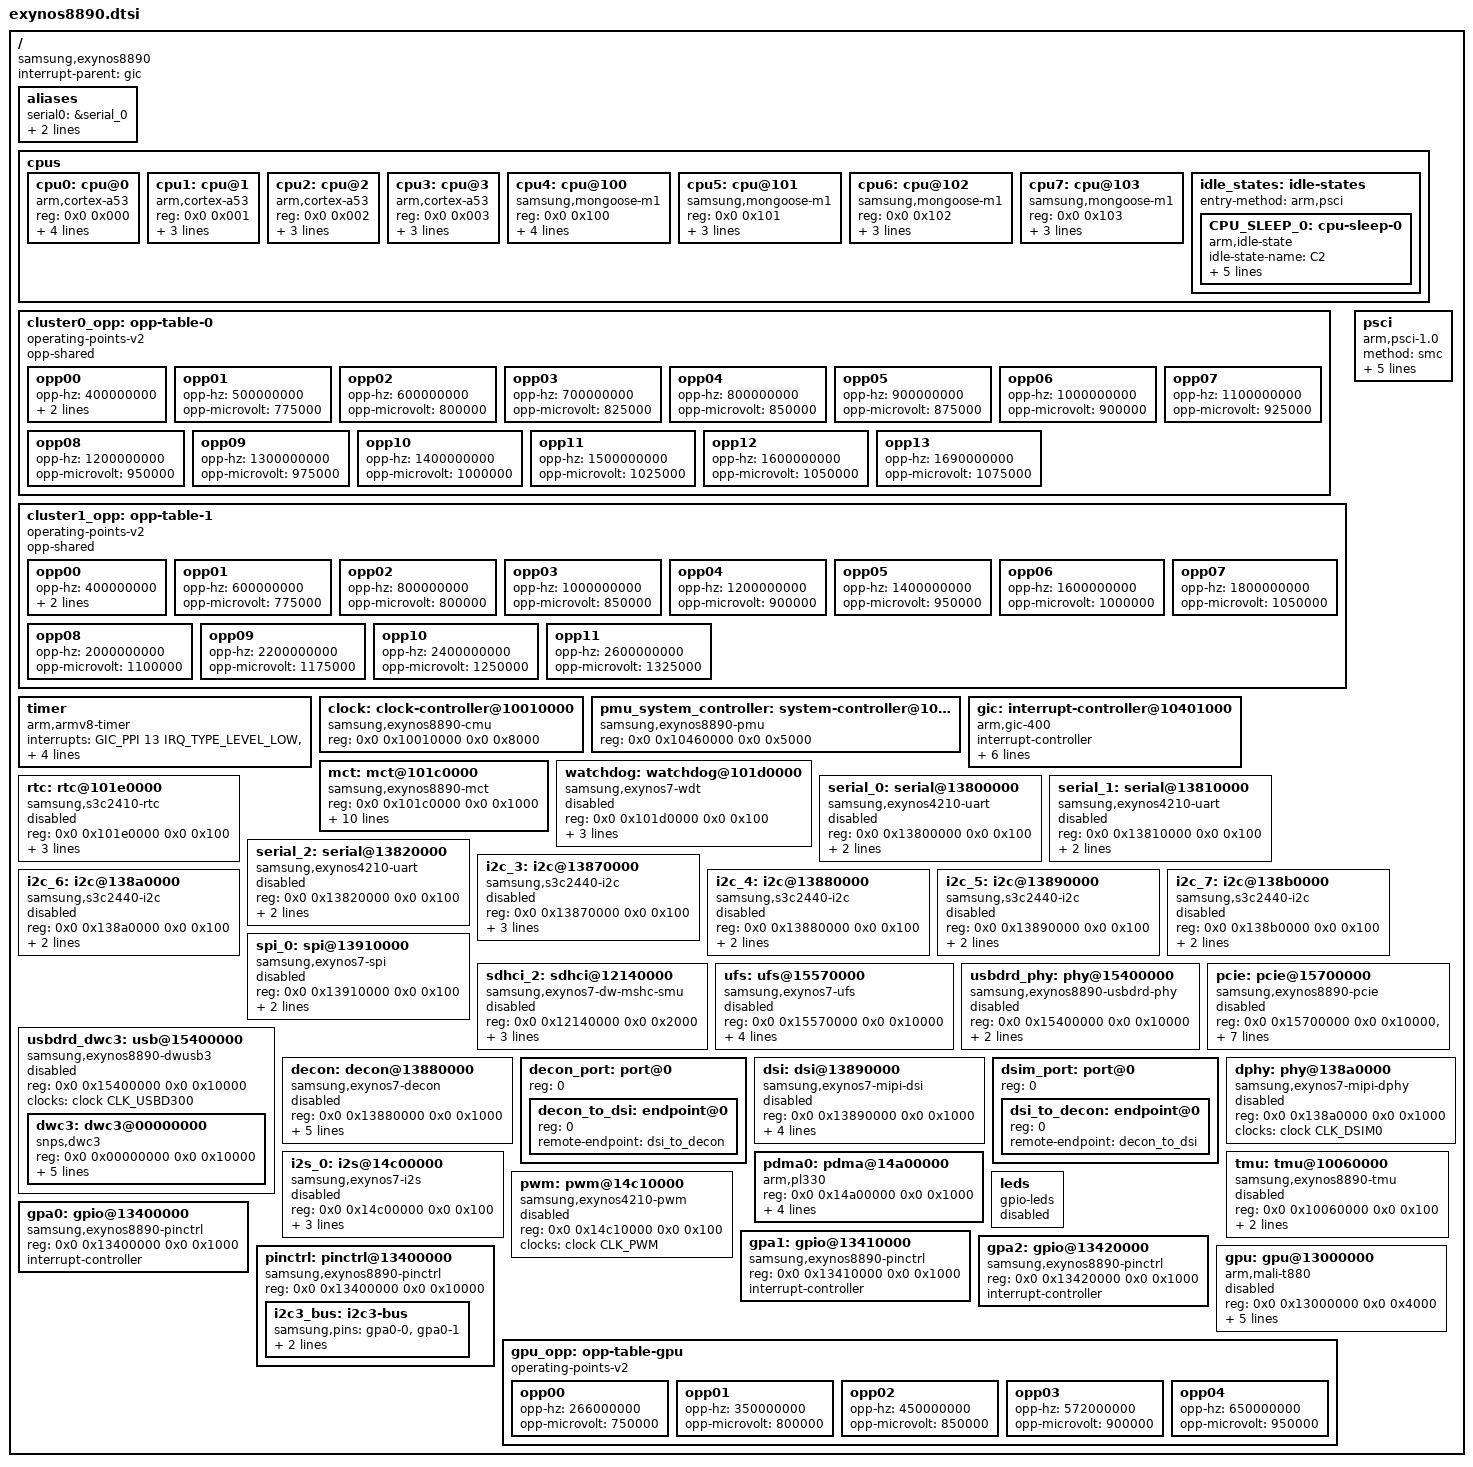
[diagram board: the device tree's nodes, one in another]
/*
 * Samsung Exynos 8890 SoC
 * Device Tree Include file
 *
 * Based on Samsung GPL kernel and upstream Exynos 8890 support.
 * This is a simplified/ported version for mainline Linux bring-up.
 */

#include <dt-bindings/interrupt-controller/arm-gic.h>
#include <dt-bindings/clock/exynos8890.h>
#include <dt-bindings/gpio/gpio.h>

/ {
	compatible = "samsung,exynos8890";
	#address-cells = <2>;
	#size-cells = <2>;

	interrupt-parent = <&gic>;

	aliases {
		serial0 = &serial_0;
		serial1 = &serial_1;
		serial2 = &serial_2;
	};

	cpus {
		#address-cells = <2>;
		#size-cells = <0>;

		cpu0: cpu@0 {
			device_type = "cpu";
			compatible = "arm,cortex-a53";
			reg = <0x0 0x000>;
			enable-method = "psci";
			clocks = <&clock CLK_ARM_CLK>;
			clock-latency = <300000>;
			operating-points-v2 = <&cluster0_opp>;
			#cooling-cells = <2>;
		};

		cpu1: cpu@1 {
			device_type = "cpu";
			compatible = "arm,cortex-a53";
			reg = <0x0 0x001>;
			enable-method = "psci";
			clocks = <&clock CLK_ARM_CLK>;
			operating-points-v2 = <&cluster0_opp>;
		};

		cpu2: cpu@2 {
			device_type = "cpu";
			compatible = "arm,cortex-a53";
			reg = <0x0 0x002>;
			enable-method = "psci";
			clocks = <&clock CLK_ARM_CLK>;
			operating-points-v2 = <&cluster0_opp>;
		};

		cpu3: cpu@3 {
			device_type = "cpu";
			compatible = "arm,cortex-a53";
			reg = <0x0 0x003>;
			enable-method = "psci";
			clocks = <&clock CLK_ARM_CLK>;
			operating-points-v2 = <&cluster0_opp>;
		};

		cpu4: cpu@100 {
			device_type = "cpu";
			compatible = "samsung,mongoose-m1";
			reg = <0x0 0x100>;
			enable-method = "psci";
			clocks = <&clock CLK_KFC_CLK>;
			clock-latency = <300000>;
			operating-points-v2 = <&cluster1_opp>;
			#cooling-cells = <2>;
		};

		cpu5: cpu@101 {
			device_type = "cpu";
			compatible = "samsung,mongoose-m1";
			reg = <0x0 0x101>;
			enable-method = "psci";
			clocks = <&clock CLK_KFC_CLK>;
			operating-points-v2 = <&cluster1_opp>;
		};

		cpu6: cpu@102 {
			device_type = "cpu";
			compatible = "samsung,mongoose-m1";
			reg = <0x0 0x102>;
			enable-method = "psci";
			clocks = <&clock CLK_KFC_CLK>;
			operating-points-v2 = <&cluster1_opp>;
		};

		cpu7: cpu@103 {
			device_type = "cpu";
			compatible = "samsung,mongoose-m1";
			reg = <0x0 0x103>;
			enable-method = "psci";
			clocks = <&clock CLK_KFC_CLK>;
			operating-points-v2 = <&cluster1_opp>;
		};

		idle_states: idle-states {
			entry-method = "arm,psci";

			CPU_SLEEP_0: cpu-sleep-0 {
				compatible = "arm,idle-state";
				idle-state-name = "C2";
				arm,psci-suspend-param = <0x0010002>;
				local-timer-stop;
				entry-latency-us = <300>;
				exit-latency-us = <400>;
				min-residency-us = <2000>;
			};
		};
	};

	cluster0_opp: opp-table-0 {
		compatible = "operating-points-v2";
		opp-shared;

		opp00 {
			opp-hz = /bits/ 64 <400000000>;
			opp-microvolt = <750000>;
			clock-latency-ns = <300000>;
		};
		opp01 {
			opp-hz = /bits/ 64 <500000000>;
			opp-microvolt = <775000>;
		};
		opp02 {
			opp-hz = /bits/ 64 <600000000>;
			opp-microvolt = <800000>;
		};
		opp03 {
			opp-hz = /bits/ 64 <700000000>;
			opp-microvolt = <825000>;
		};
		opp04 {
			opp-hz = /bits/ 64 <800000000>;
			opp-microvolt = <850000>;
		};
		opp05 {
			opp-hz = /bits/ 64 <900000000>;
			opp-microvolt = <875000>;
		};
		opp06 {
			opp-hz = /bits/ 64 <1000000000>;
			opp-microvolt = <900000>;
		};
		opp07 {
			opp-hz = /bits/ 64 <1100000000>;
			opp-microvolt = <925000>;
		};
		opp08 {
			opp-hz = /bits/ 64 <1200000000>;
			opp-microvolt = <950000>;
		};
		opp09 {
			opp-hz = /bits/ 64 <1300000000>;
			opp-microvolt = <975000>;
		};
		opp10 {
			opp-hz = /bits/ 64 <1400000000>;
			opp-microvolt = <1000000>;
		};
		opp11 {
			opp-hz = /bits/ 64 <1500000000>;
			opp-microvolt = <1025000>;
		};
		opp12 {
			opp-hz = /bits/ 64 <1600000000>;
			opp-microvolt = <1050000>;
		};
		opp13 {
			opp-hz = /bits/ 64 <1690000000>;
			opp-microvolt = <1075000>;
		};
	};

	cluster1_opp: opp-table-1 {
		compatible = "operating-points-v2";
		opp-shared;

		opp00 {
			opp-hz = /bits/ 64 <400000000>;
			opp-microvolt = <750000>;
			clock-latency-ns = <300000>;
		};
		opp01 {
			opp-hz = /bits/ 64 <600000000>;
			opp-microvolt = <775000>;
		};
		opp02 {
			opp-hz = /bits/ 64 <800000000>;
			opp-microvolt = <800000>;
		};
		opp03 {
			opp-hz = /bits/ 64 <1000000000>;
			opp-microvolt = <850000>;
		};
		opp04 {
			opp-hz = /bits/ 64 <1200000000>;
			opp-microvolt = <900000>;
		};
		opp05 {
			opp-hz = /bits/ 64 <1400000000>;
			opp-microvolt = <950000>;
		};
		opp06 {
			opp-hz = /bits/ 64 <1600000000>;
			opp-microvolt = <1000000>;
		};
		opp07 {
			opp-hz = /bits/ 64 <1800000000>;
			opp-microvolt = <1050000>;
		};
		opp08 {
			opp-hz = /bits/ 64 <2000000000>;
			opp-microvolt = <1100000>;
		};
		opp09 {
			opp-hz = /bits/ 64 <2200000000>;
			opp-microvolt = <1175000>;
		};
		opp10 {
			opp-hz = /bits/ 64 <2400000000>;
			opp-microvolt = <1250000>;
		};
		opp11 {
			opp-hz = /bits/ 64 <2600000000>;
			opp-microvolt = <1325000>;
		};
	};

	psci {
		compatible = "arm,psci-1.0";
		method = "smc";
		cpu_suspend = <0xc4000001>;
		cpu_off = <0x84000002>;
		cpu_on = <0xc4000003>;
		system_off = <0x84000008>;
		system_reset = <0x84000009>;
	};

	timer {
		compatible = "arm,armv8-timer";
		interrupts = <GIC_PPI 13 IRQ_TYPE_LEVEL_LOW>,
			     <GIC_PPI 14 IRQ_TYPE_LEVEL_LOW>,
			     <GIC_PPI 11 IRQ_TYPE_LEVEL_LOW>,
			     <GIC_PPI 10 IRQ_TYPE_LEVEL_LOW>;
		clock-frequency = <24000000>;
	};

	/* Clock controller */
	clock: clock-controller@10010000 {
		compatible = "samsung,exynos8890-cmu";
		reg = <0x0 0x10010000 0x0 0x8000>;
		#clock-cells = <1>;
	};

	/* Power Management Unit */
	pmu_system_controller: system-controller@10460000 {
		compatible = "samsung,exynos8890-pmu", "syscon";
		reg = <0x0 0x10460000 0x0 0x5000>;
	};

	/* GIC - Generic Interrupt Controller */
	gic: interrupt-controller@10401000 {
		compatible = "arm,gic-400";
		#interrupt-cells = <3>;
		#address-cells = <0>;
		interrupt-controller;
		reg = <0x0 0x10401000 0x0 0x1000>,
		      <0x0 0x10402000 0x0 0x2000>,
		      <0x0 0x10404000 0x0 0x2000>,
		      <0x0 0x10406000 0x0 0x2000>;
		interrupts = <GIC_PPI 9 (GIC_CPU_MASK_SIMPLE(8) | IRQ_TYPE_LEVEL_HIGH)>;
	};

	/* MCT - Multi Core Timer */
	mct: mct@101c0000 {
		compatible = "samsung,exynos8890-mct";
		reg = <0x0 0x101c0000 0x0 0x1000>;
		interrupts = <GIC_SPI 120 IRQ_TYPE_LEVEL_HIGH>,
			     <GIC_SPI 121 IRQ_TYPE_LEVEL_HIGH>,
			     <GIC_SPI 122 IRQ_TYPE_LEVEL_HIGH>,
			     <GIC_SPI 123 IRQ_TYPE_LEVEL_HIGH>,
			     <GIC_SPI 124 IRQ_TYPE_LEVEL_HIGH>,
			     <GIC_SPI 125 IRQ_TYPE_LEVEL_HIGH>,
			     <GIC_SPI 126 IRQ_TYPE_LEVEL_HIGH>,
			     <GIC_SPI 127 IRQ_TYPE_LEVEL_HIGH>,
			     <GIC_SPI 128 IRQ_TYPE_LEVEL_HIGH>;
		clocks = <&clock CLK_FIN_PLL>, <&clock CLK_MCT>;
		clock-names = "fin_pll", "mct";
	};

	/* Watchdog */
	watchdog: watchdog@101d0000 {
		compatible = "samsung,exynos7-wdt";
		reg = <0x0 0x101d0000 0x0 0x100>;
		interrupts = <GIC_SPI 129 IRQ_TYPE_LEVEL_HIGH>;
		clocks = <&clock CLK_WDT>;
		clock-names = "watchdog";
		samsung,syscon-phandle = <&pmu_system_controller>;
		status = "disabled";
	};

	/* RTC */
	rtc: rtc@101e0000 {
		compatible = "samsung,s3c2410-rtc";
		reg = <0x0 0x101e0000 0x0 0x100>;
		interrupts = <GIC_SPI 130 IRQ_TYPE_LEVEL_HIGH>,
			     <GIC_SPI 131 IRQ_TYPE_LEVEL_HIGH>;
		clocks = <&clock CLK_RTC>;
		clock-names = "rtc";
		status = "disabled";
	};

	/* UART 0 - Debug */
	serial_0: serial@13800000 {
		compatible = "samsung,exynos4210-uart";
		reg = <0x0 0x13800000 0x0 0x100>;
		interrupts = <GIC_SPI 136 IRQ_TYPE_LEVEL_HIGH>;
		clocks = <&clock CLK_UART0>, <&clock CLK_SCLK_UART0>;
		clock-names = "uart", "clk_uart_baud0";
		status = "disabled";
	};

	/* UART 1 - BT */
	serial_1: serial@13810000 {
		compatible = "samsung,exynos4210-uart";
		reg = <0x0 0x13810000 0x0 0x100>;
		interrupts = <GIC_SPI 137 IRQ_TYPE_LEVEL_HIGH>;
		clocks = <&clock CLK_UART1>, <&clock CLK_SCLK_UART1>;
		clock-names = "uart", "clk_uart_baud0";
		status = "disabled";
	};

	/* UART 2 - GPS/Debug */
	serial_2: serial@13820000 {
		compatible = "samsung,exynos4210-uart";
		reg = <0x0 0x13820000 0x0 0x100>;
		interrupts = <GIC_SPI 138 IRQ_TYPE_LEVEL_HIGH>;
		clocks = <&clock CLK_UART2>, <&clock CLK_SCLK_UART2>;
		clock-names = "uart", "clk_uart_baud0";
		status = "disabled";
	};

	/* I2C controllers */
	i2c_3: i2c@13870000 {
		compatible = "samsung,s3c2440-i2c";
		reg = <0x0 0x13870000 0x0 0x100>;
		interrupts = <GIC_SPI 144 IRQ_TYPE_LEVEL_HIGH>;
		clocks = <&clock CLK_I2C3>;
		clock-names = "i2c";
		pinctrl-names = "default";
		pinctrl-0 = <&i2c3_bus>;
		#address-cells = <1>;
		#size-cells = <0>;
		status = "disabled";
	};

	i2c_4: i2c@13880000 {
		compatible = "samsung,s3c2440-i2c";
		reg = <0x0 0x13880000 0x0 0x100>;
		interrupts = <GIC_SPI 145 IRQ_TYPE_LEVEL_HIGH>;
		clocks = <&clock CLK_I2C4>;
		clock-names = "i2c";
		#address-cells = <1>;
		#size-cells = <0>;
		status = "disabled";
	};

	i2c_5: i2c@13890000 {
		compatible = "samsung,s3c2440-i2c";
		reg = <0x0 0x13890000 0x0 0x100>;
		interrupts = <GIC_SPI 146 IRQ_TYPE_LEVEL_HIGH>;
		clocks = <&clock CLK_I2C5>;
		clock-names = "i2c";
		#address-cells = <1>;
		#size-cells = <0>;
		status = "disabled";
	};

	i2c_6: i2c@138a0000 {
		compatible = "samsung,s3c2440-i2c";
		reg = <0x0 0x138a0000 0x0 0x100>;
		interrupts = <GIC_SPI 147 IRQ_TYPE_LEVEL_HIGH>;
		clocks = <&clock CLK_I2C6>;
		clock-names = "i2c";
		#address-cells = <1>;
		#size-cells = <0>;
		status = "disabled";
	};

	i2c_7: i2c@138b0000 {
		compatible = "samsung,s3c2440-i2c";
		reg = <0x0 0x138b0000 0x0 0x100>;
		interrupts = <GIC_SPI 148 IRQ_TYPE_LEVEL_HIGH>;
		clocks = <&clock CLK_I2C7>;
		clock-names = "i2c";
		#address-cells = <1>;
		#size-cells = <0>;
		status = "disabled";
	};

	/* SPI */
	spi_0: spi@13910000 {
		compatible = "samsung,exynos7-spi";
		reg = <0x0 0x13910000 0x0 0x100>;
		interrupts = <GIC_SPI 152 IRQ_TYPE_LEVEL_HIGH>;
		clocks = <&clock CLK_SPI0>, <&clock CLK_SCLK_SPI0>;
		clock-names = "spi", "spi_busclk0";
		#address-cells = <1>;
		#size-cells = <0>;
		status = "disabled";
	};

	/* SDHCI - SD card */
	sdhci_2: sdhci@12140000 {
		compatible = "samsung,exynos7-dw-mshc-smu";
		reg = <0x0 0x12140000 0x0 0x2000>;
		interrupts = <GIC_SPI 160 IRQ_TYPE_LEVEL_HIGH>;
		clocks = <&clock CLK_MMC2>, <&clock CLK_SCLK_MMC2>;
		clock-names = "biu", "ciu";
		fifo-depth = <0x40>;
		status = "disabled";
	};

	/* UFS */
	ufs: ufs@15570000 {
		compatible = "samsung,exynos7-ufs";
		reg = <0x0 0x15570000 0x0 0x10000>;
		interrupts = <GIC_SPI 200 IRQ_TYPE_LEVEL_HIGH>;
		clocks = <&clock CLK_UFS>, <&clock CLK_SCLK_UFS_SUNLIKE>;
		clock-names = "ufs", "clk_ufs_sunlike";
		freq-table-hz = <0 0>, <0 0>;
		status = "disabled";
	};

	/* USB DRD */
	usbdrd_phy: phy@15400000 {
		compatible = "samsung,exynos8890-usbdrd-phy";
		reg = <0x0 0x15400000 0x0 0x10000>;
		clocks = <&clock CLK_USBD300>, <&clock CLK_USBPHY300>;
		clock-names = "phy", "ref";
		samsung,pmu-syscon = <&pmu_system_controller>;
		#phy-cells = <0>;
		status = "disabled";
	};

	usbdrd_dwc3: usb@15400000 {
		compatible = "samsung,exynos8890-dwusb3";
		reg = <0x0 0x15400000 0x0 0x10000>;
		ranges;
		clocks = <&clock CLK_USBD300>;
		clock-names = "usbdrd30";
		#address-cells = <2>;
		#size-cells = <2>;
		status = "disabled";

		dwc3: dwc3@00000000 {
			compatible = "snps,dwc3";
			reg = <0x0 0x00000000 0x0 0x10000>;
			interrupts = <GIC_SPI 201 IRQ_TYPE_LEVEL_HIGH>;
			phys = <&usbdrd_phy>;
			phy-names = "usb2-phy";
			snps,quirk-frame-length-adjustment = <0x20>;
			snps,refclk_fladj;
			dr_mode = "peripheral";
		};
	};

	/* PCIe */
	pcie: pcie@15700000 {
		compatible = "samsung,exynos8890-pcie";
		reg = <0x0 0x15700000 0x0 0x10000>,
		      <0x0 0x40000000 0x0 0x100000>;
		reg-names = "elbi", "config";
		#address-cells = <3>;
		#size-cells = <2>;
		device_type = "pci";
		ranges = <0x81000000 0 0 0x0 0x40100000 0 0x10000>,
			 <0x82000000 0 0 0x0 0x50000000 0 0x10000000>;
		interrupts = <GIC_SPI 250 IRQ_TYPE_LEVEL_HIGH>;
		clocks = <&clock CLK_PCIE>, <&clock CLK_SCLK_PCIE_100>;
		clock-names = "pcie", "pcie_bus";
		#interrupt-cells = <1>;
		interrupt-map-mask = <0 0 0 0>;
		interrupt-map = <0 0 0 0 &gic GIC_SPI 250 IRQ_TYPE_LEVEL_HIGH>;
		status = "disabled";
	};

	/* DECON - Display controller */
	decon: decon@13880000 {
		compatible = "samsung,exynos7-decon";
		reg = <0x0 0x13880000 0x0 0x1000>;
		interrupts = <GIC_SPI 180 IRQ_TYPE_LEVEL_HIGH>,
			     <GIC_SPI 181 IRQ_TYPE_LEVEL_HIGH>,
			     <GIC_SPI 182 IRQ_TYPE_LEVEL_HIGH>;
		clocks = <&clock CLK_DECON>;
		clock-names = "decon";
		status = "disabled";

		ports = <&decon_port>;
	};

	decon_port: port@0 {
		reg = <0>;
		#address-cells = <1>;
		#size-cells = <0>;

		decon_to_dsi: endpoint@0 {
			reg = <0>;
			remote-endpoint = <&dsi_to_decon>;
		};
	};

	/* DSI */
	dsi: dsi@13890000 {
		compatible = "samsung,exynos7-mipi-dsi";
		reg = <0x0 0x13890000 0x0 0x1000>;
		interrupts = <GIC_SPI 183 IRQ_TYPE_LEVEL_HIGH>;
		clocks = <&clock CLK_DSIM0>;
		clock-names = "dsim";
		phys = <&dphy>;
		phy-names = "dphy";
		status = "disabled";

		ports = <&dsim_port>;
	};

	dsim_port: port@0 {
		reg = <0>;
		#address-cells = <1>;
		#size-cells = <0>;

		dsi_to_decon: endpoint@0 {
			reg = <0>;
			remote-endpoint = <&decon_to_dsi>;
		};
	};

	/* D-PHY for DSI */
	dphy: phy@138a0000 {
		compatible = "samsung,exynos7-mipi-dphy";
		reg = <0x0 0x138a0000 0x0 0x1000>;
		clocks = <&clock CLK_DSIM0>;
		clock-names = "dphy";
		#phy-cells = <0>;
		status = "disabled";
	};

	/* I2S - Audio */
	i2s_0: i2s@14c00000 {
		compatible = "samsung,exynos7-i2s";
		reg = <0x0 0x14c00000 0x0 0x100>;
		interrupts = <GIC_SPI 210 IRQ_TYPE_LEVEL_HIGH>;
		clocks = <&clock CLK_I2S>;
		clock-names = "iis";
		dmas = <&pdma0 0>, <&pdma0 1>;
		dma-names = "tx", "rx";
		status = "disabled";
	};

	/* PDMA - Peripheral DMA */
	pdma0: pdma@14a00000 {
		compatible = "arm,pl330", "arm,primecell";
		reg = <0x0 0x14a00000 0x0 0x1000>;
		interrupts = <GIC_SPI 220 IRQ_TYPE_LEVEL_HIGH>;
		clocks = <&clock CLK_PDMA0>;
		clock-names = "apb_pclk";
		#dma-cells = <1>;
		#dma-channels = <8>;
		#dma-requests = <32>;
	};

	/* TMU - Thermal Management */
	tmu: tmu@10060000 {
		compatible = "samsung,exynos8890-tmu";
		reg = <0x0 0x10060000 0x0 0x100>;
		interrupts = <GIC_SPI 230 IRQ_TYPE_LEVEL_HIGH>;
		clocks = <&clock CLK_TMU>;
		clock-names = "tmu_apbif";
		status = "disabled";
	};

	/* PWM - For LEDs */
	pwm: pwm@14c10000 {
		compatible = "samsung,exynos4210-pwm";
		reg = <0x0 0x14c10000 0x0 0x100>;
		clocks = <&clock CLK_PWM>;
		clock-names = "timers";
		#pwm-cells = <3>;
		status = "disabled";
	};

	/* LEDs */
	leds: leds {
		compatible = "gpio-leds";
		status = "disabled";
	};

	/* GPIO controllers */
	gpa0: gpio@13400000 {
		compatible = "samsung,exynos8890-pinctrl";
		reg = <0x0 0x13400000 0x0 0x1000>;
		#address-cells = <1>;
		#size-cells = <0>;
		interrupt-controller;
		#interrupt-cells = <2>;
	};

	gpa1: gpio@13410000 {
		compatible = "samsung,exynos8890-pinctrl";
		reg = <0x0 0x13410000 0x0 0x1000>;
		#address-cells = <1>;
		#size-cells = <0>;
		interrupt-controller;
		#interrupt-cells = <2>;
	};

	gpa2: gpio@13420000 {
		compatible = "samsung,exynos8890-pinctrl";
		reg = <0x0 0x13420000 0x0 0x1000>;
		#address-cells = <1>;
		#size-cells = <0>;
		interrupt-controller;
		#interrupt-cells = <2>;
	};

	/* Pinctrl */
	pinctrl: pinctrl@13400000 {
		compatible = "samsung,exynos8890-pinctrl";
		reg = <0x0 0x13400000 0x0 0x10000>;

		i2c3_bus: i2c3-bus {
			samsung,pins = "gpa0-0", "gpa0-1";
			samsung,pin-function = <2>;
			samsung,pin-drv = <0>;
		};
	};

	/* Mali-T880 GPU */
	gpu: gpu@13000000 {
		compatible = "arm,mali-t880";
		reg = <0x0 0x13000000 0x0 0x4000>;
		interrupts = <GIC_SPI 300 IRQ_TYPE_LEVEL_HIGH>,
			     <GIC_SPI 301 IRQ_TYPE_LEVEL_HIGH>,
			     <GIC_SPI 302 IRQ_TYPE_LEVEL_HIGH>;
		interrupt-names = "JOB", "MMU", "GPU";
		clocks = <&clock CLK_G3D>;
		clock-names = "core";
		operating-points-v2 = <&gpu_opp>;
		status = "disabled";
	};

	gpu_opp: opp-table-gpu {
		compatible = "operating-points-v2";

		opp00 {
			opp-hz = /bits/ 64 <266000000>;
			opp-microvolt = <750000>;
		};
		opp01 {
			opp-hz = /bits/ 64 <350000000>;
			opp-microvolt = <800000>;
		};
		opp02 {
			opp-hz = /bits/ 64 <450000000>;
			opp-microvolt = <850000>;
		};
		opp03 {
			opp-hz = /bits/ 64 <572000000>;
			opp-microvolt = <900000>;
		};
		opp04 {
			opp-hz = /bits/ 64 <650000000>;
			opp-microvolt = <950000>;
		};
	};
};
